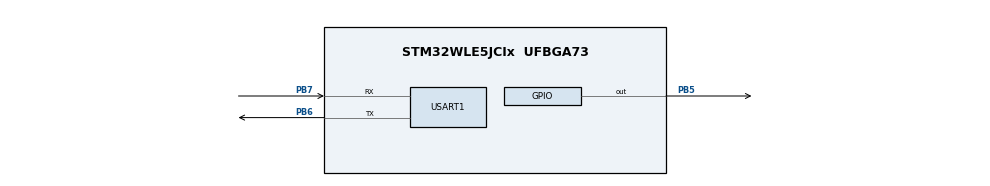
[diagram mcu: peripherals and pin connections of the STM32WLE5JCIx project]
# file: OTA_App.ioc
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Mcu.Family=STM32WL
Mcu.Name=STM32WLE5JCIx
Mcu.Package=UFBGA73
NVIC.PriorityGroup=NVIC_PRIORITYGROUP_4
PB5.Signal=GPIO_Output
PB6.Mode=Multiprocessor_communication
PB6.Signal=USART1_TX
PB7.Mode=Multiprocessor_communication
PB7.Signal=USART1_RX
ProjectManager.HeapSize=0x200
ProjectManager.StackSize=0x400
ProjectManager.TargetToolchain=STM32CubeIDE
RCC.HSE_VALUE=8000000
RCC.HSI_VALUE=16000000
RCC.LSE_VALUE=32768
RCC.VCOOutputFreq_Value=32000000
USART1.VirtualMode-Multiprocessor_communication=VM_ASYNC
board=custom

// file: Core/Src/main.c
/* USER CODE BEGIN Header */
/**
  ******************************************************************************
  * @file           : main.c
  * @brief          : Main program body
  ******************************************************************************
  * @attention
  *
  * <h2><center>&copy; Copyright (c) 2021 STMicroelectronics.
  * All rights reserved.</center></h2>
  *
  * This software component is licensed by ST under BSD 3-Clause license,
  * the "License"; You may not use this file except in compliance with the
  * License. You may obtain a copy of the License at:
  *                        opensource.org/licenses/BSD-3-Clause
  *
  ******************************************************************************
  */
/* USER CODE END Header */
#include "main.h"

/* USER CODE BEGIN Includes */
#include <stdio.h>
#include <string.h>
#include <stdlib.h>
#include "system_ota.h"
/* USER CODE END Includes */

UART_HandleTypeDef huart1;

/* USER CODE BEGIN PV */
SystemParamTypeDef SystemParam;
/* USER CODE END PV */

void SystemClock_Config(void);
static void MX_GPIO_Init(void);
static void MX_USART1_UART_Init(void);
/* USER CODE BEGIN PFP */
#define PUTCHAR_PROTOTYPE int __io_putchar(int ch)
/* USER CODE END PFP */

int main(void)
{
  /* USER CODE BEGIN 1 */
  uint8_t key = 0;

  SCB->VTOR = 0x08010000;
  /* USER CODE END 1 */

  /* MCU Configuration--------------------------------------------------------*/

  /* Reset of all peripherals, Initializes the Flash interface and the Systick. */
  HAL_Init();

  /* Configure the system clock */
  SystemClock_Config();

  /* Initialize all configured peripherals */
  MX_GPIO_Init();
  MX_USART1_UART_Init();
  /* USER CODE BEGIN 2 */
  System_ParamReadCheckUpdate(&SystemParam);
  /* USER CODE END 2 */

  /* Infinite loop */
  /* USER CODE BEGIN WHILE */
  while (1)
  {
    printf("\r\n=================== Main Menu ============================\r\n\n");
    printf("  IAP:Download user application to the internal Flash ----- 0\r\n\n");
    printf("  Current System APP Version: 0x%08lX\r\n", SystemParam.App_Version);
    /* Clean the input path */
    __HAL_UART_FLUSH_DRREGISTER(&huart1);
    if(HAL_UART_Receive(&huart1, &key, 1, HAL_MAX_DELAY) == HAL_OK)
    {
      if(key == '1')
      {
        SystemParam_OTA(&SystemParam);
      }
    }
    /* USER CODE END WHILE */

  }
}

void SystemClock_Config(void)
{
  RCC_OscInitTypeDef RCC_OscInitStruct = {0};
  RCC_ClkInitTypeDef RCC_ClkInitStruct = {0};

  /** Configure the main internal regulator output voltage
  */
  __HAL_PWR_VOLTAGESCALING_CONFIG(PWR_REGULATOR_VOLTAGE_SCALE2);
  /** Initializes the CPU, AHB and APB busses clocks
  */
  RCC_OscInitStruct.OscillatorType = RCC_OSCILLATORTYPE_MSI;
  RCC_OscInitStruct.MSIState = RCC_MSI_ON;
  RCC_OscInitStruct.MSICalibrationValue = RCC_MSICALIBRATION_DEFAULT;
  RCC_OscInitStruct.MSIClockRange = RCC_MSIRANGE_6;
  RCC_OscInitStruct.PLL.PLLState = RCC_PLL_NONE;
  if (HAL_RCC_OscConfig(&RCC_OscInitStruct) != HAL_OK)
  {
    Error_Handler();
  }
  /** Configure the SYSCLKSource, HCLK, PCLK1 and PCLK2 clocks dividers
  */
  RCC_ClkInitStruct.ClockType = RCC_CLOCKTYPE_HCLK3|RCC_CLOCKTYPE_HCLK
                              |RCC_CLOCKTYPE_SYSCLK|RCC_CLOCKTYPE_PCLK1
                              |RCC_CLOCKTYPE_PCLK2;
  RCC_ClkInitStruct.SYSCLKSource = RCC_SYSCLKSOURCE_MSI;
  RCC_ClkInitStruct.AHBCLKDivider = RCC_SYSCLK_DIV1;
  RCC_ClkInitStruct.APB1CLKDivider = RCC_HCLK_DIV1;
  RCC_ClkInitStruct.APB2CLKDivider = RCC_HCLK_DIV1;
  RCC_ClkInitStruct.AHBCLK3Divider = RCC_SYSCLK_DIV1;

  if (HAL_RCC_ClockConfig(&RCC_ClkInitStruct, FLASH_LATENCY_0) != HAL_OK)
  {
    Error_Handler();
  }
}

static void MX_USART1_UART_Init(void)
{

  huart1.Instance = USART1;
  huart1.Init.BaudRate = 115200;
  huart1.Init.WordLength = UART_WORDLENGTH_8B;
  huart1.Init.StopBits = UART_STOPBITS_1;
  huart1.Init.Parity = UART_PARITY_NONE;
  huart1.Init.Mode = UART_MODE_TX_RX;
  huart1.Init.HwFlowCtl = UART_HWCONTROL_NONE;
  huart1.Init.OverSampling = UART_OVERSAMPLING_16;
  huart1.Init.OneBitSampling = UART_ONE_BIT_SAMPLE_DISABLE;
  huart1.Init.ClockPrescaler = UART_PRESCALER_DIV1;
  huart1.AdvancedInit.AdvFeatureInit = UART_ADVFEATURE_NO_INIT;
  if (HAL_MultiProcessor_Init(&huart1, 0, UART_WAKEUPMETHOD_IDLELINE) != HAL_OK)
  {
    Error_Handler();
  }
  if (HAL_UARTEx_SetTxFifoThreshold(&huart1, UART_TXFIFO_THRESHOLD_1_8) != HAL_OK)
  {
    Error_Handler();
  }
  if (HAL_UARTEx_SetRxFifoThreshold(&huart1, UART_RXFIFO_THRESHOLD_1_8) != HAL_OK)
  {
    Error_Handler();
  }
  if (HAL_UARTEx_DisableFifoMode(&huart1) != HAL_OK)
  {
    Error_Handler();
  }

}

static void MX_GPIO_Init(void)
{
  GPIO_InitTypeDef GPIO_InitStruct = {0};

  /* GPIO Ports Clock Enable */
  __HAL_RCC_GPIOB_CLK_ENABLE();

  /*Configure GPIO pin Output Level */
  HAL_GPIO_WritePin(GPIOB, GPIO_PIN_5, GPIO_PIN_RESET);

  /*Configure GPIO pin : PB5 */
  GPIO_InitStruct.Pin = GPIO_PIN_5;
  GPIO_InitStruct.Mode = GPIO_MODE_OUTPUT_PP;
  GPIO_InitStruct.Pull = GPIO_NOPULL;
  GPIO_InitStruct.Speed = GPIO_SPEED_FREQ_LOW;
  HAL_GPIO_Init(GPIOB, &GPIO_InitStruct);

}

/* USER CODE BEGIN 4 */
/**
  * @brief  Retargets the C library printf function to the USART.
  * @param  None
  * @retval None
  */
PUTCHAR_PROTOTYPE
{
  /* Place your implementation of fputc here */
  /* e.g. write a character to the USART2 and Loop until the end of transmission */
  HAL_UART_Transmit(&huart1, (uint8_t *)&ch, 1, 0xFFFF);

  return ch;
}
/* USER CODE END 4 */

void Error_Handler(void)
{
  __disable_irq();
  while (1)
  {
  }
}

/************************ (C) COPYRIGHT STMicroelectronics *****END OF FILE****/
